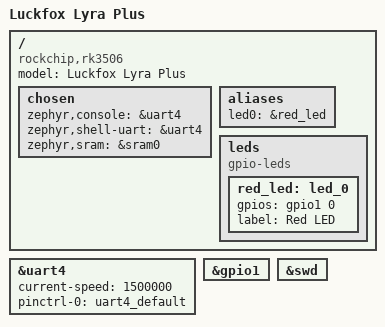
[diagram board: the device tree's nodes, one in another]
/*
 * Copyright (c) 2026 Marcin Bober
 *
 * SPDX-License-Identifier: Apache-2.0
 */

/dts-v1/;

#include <rockchip/rk3506.dtsi>
#include "luckfox_lyra_plus_rk3506-pinctrl.dtsi"

/ {
	model = "Luckfox Lyra Plus";
	compatible = "rockchip,rk3506";

	chosen {
		zephyr,console = &uart4;
		zephyr,shell-uart = &uart4;
		zephyr,sram = &sram0;
	};

	aliases {
		led0 = &red_led;
	};

	leds {
		compatible = "gpio-leds";
		red_led: led_0 {
			gpios = <&gpio1 0 GPIO_ACTIVE_HIGH>;
			label = "Red LED";
		};
	};
};

&uart4 {
	current-speed = <1500000>;
	pinctrl-0 = <&uart4_default>;
	pinctrl-names = "default";
	status = "okay";
};

&gpio1 {
	status = "okay";
};

&swd {
	status = "okay";
};
